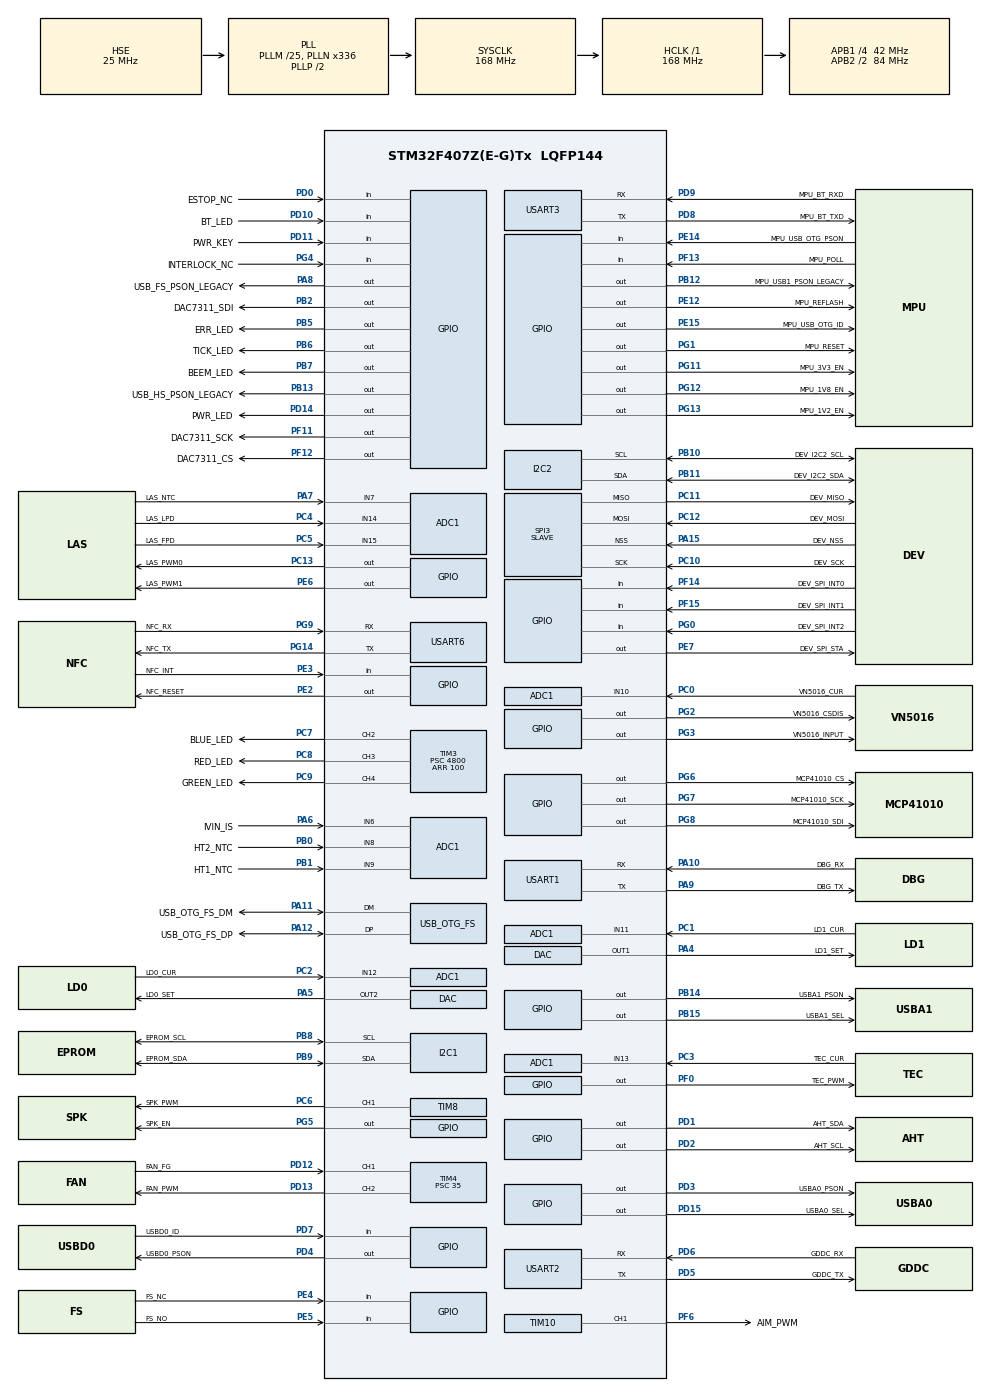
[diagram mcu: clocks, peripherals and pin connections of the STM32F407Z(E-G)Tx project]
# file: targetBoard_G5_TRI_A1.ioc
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ADC1.Channel-0\#ChannelRegularConversion=ADC_CHANNEL_6
ADC1.Channel-1\#ChannelRegularConversion=ADC_CHANNEL_7
ADC1.Channel-10\#ChannelRegularConversion=ADC_CHANNEL_TEMPSENSOR
ADC1.Channel-11\#ChannelRegularConversion=ADC_CHANNEL_VREFINT
ADC1.Channel-12\#ChannelRegularConversion=ADC_CHANNEL_VBAT
ADC1.Channel-2\#ChannelRegularConversion=ADC_CHANNEL_8
ADC1.Channel-3\#ChannelRegularConversion=ADC_CHANNEL_9
ADC1.Channel-4\#ChannelRegularConversion=ADC_CHANNEL_10
ADC1.Channel-5\#ChannelRegularConversion=ADC_CHANNEL_11
ADC1.Channel-6\#ChannelRegularConversion=ADC_CHANNEL_12
ADC1.Channel-7\#ChannelRegularConversion=ADC_CHANNEL_13
ADC1.Channel-8\#ChannelRegularConversion=ADC_CHANNEL_14
ADC1.Channel-9\#ChannelRegularConversion=ADC_CHANNEL_15
ADC1.ContinuousConvMode=ENABLE
ADC1.DMAContinuousRequests=ENABLE
ADC1.NbrOfConversion=13
ADC1.NbrOfConversionFlag=1
ADC1.Rank-0\#ChannelRegularConversion=1
ADC1.Rank-1\#ChannelRegularConversion=2
ADC1.Rank-10\#ChannelRegularConversion=11
ADC1.Rank-11\#ChannelRegularConversion=12
ADC1.Rank-12\#ChannelRegularConversion=13
ADC1.Rank-2\#ChannelRegularConversion=3
ADC1.Rank-3\#ChannelRegularConversion=4
ADC1.Rank-4\#ChannelRegularConversion=5
ADC1.Rank-5\#ChannelRegularConversion=6
ADC1.Rank-6\#ChannelRegularConversion=7
ADC1.Rank-7\#ChannelRegularConversion=8
ADC1.Rank-8\#ChannelRegularConversion=9
ADC1.Rank-9\#ChannelRegularConversion=10
ADC1.SamplingTime-0\#ChannelRegularConversion=ADC_SAMPLETIME_144CYCLES
ADC1.SamplingTime-1\#ChannelRegularConversion=ADC_SAMPLETIME_144CYCLES
ADC1.SamplingTime-10\#ChannelRegularConversion=ADC_SAMPLETIME_144CYCLES
ADC1.SamplingTime-11\#ChannelRegularConversion=ADC_SAMPLETIME_144CYCLES
ADC1.SamplingTime-12\#ChannelRegularConversion=ADC_SAMPLETIME_144CYCLES
ADC1.SamplingTime-2\#ChannelRegularConversion=ADC_SAMPLETIME_144CYCLES
ADC1.SamplingTime-3\#ChannelRegularConversion=ADC_SAMPLETIME_144CYCLES
ADC1.SamplingTime-4\#ChannelRegularConversion=ADC_SAMPLETIME_144CYCLES
ADC1.SamplingTime-5\#ChannelRegularConversion=ADC_SAMPLETIME_144CYCLES
ADC1.SamplingTime-6\#ChannelRegularConversion=ADC_SAMPLETIME_144CYCLES
ADC1.SamplingTime-7\#ChannelRegularConversion=ADC_SAMPLETIME_144CYCLES
ADC1.SamplingTime-8\#ChannelRegularConversion=ADC_SAMPLETIME_144CYCLES
ADC1.SamplingTime-9\#ChannelRegularConversion=ADC_SAMPLETIME_144CYCLES
ADC1.ScanConvMode=ENABLE
ADC1.master=1
DAC.DAC_Trigger=DAC_TRIGGER_NONE
DAC.DAC_Trigger2=DAC_TRIGGER_NONE
Dma.ADC1.0.Direction=DMA_PERIPH_TO_MEMORY
Dma.ADC1.0.FIFOMode=DMA_FIFOMODE_DISABLE
Dma.ADC1.0.Instance=DMA2_Stream0
Dma.ADC1.0.MemDataAlignment=DMA_MDATAALIGN_HALFWORD
Dma.ADC1.0.MemInc=DMA_MINC_ENABLE
Dma.ADC1.0.Mode=DMA_NORMAL
Dma.ADC1.0.PeriphDataAlignment=DMA_PDATAALIGN_HALFWORD
Dma.ADC1.0.PeriphInc=DMA_PINC_DISABLE
Dma.ADC1.0.Priority=DMA_PRIORITY_LOW
Dma.Request0=ADC1
Dma.Request1=USART1_RX
Dma.USART1_RX.1.Direction=DMA_PERIPH_TO_MEMORY
Dma.USART1_RX.1.FIFOMode=DMA_FIFOMODE_DISABLE
Dma.USART1_RX.1.Instance=DMA2_Stream2
Dma.USART1_RX.1.MemDataAlignment=DMA_MDATAALIGN_BYTE
Dma.USART1_RX.1.MemInc=DMA_MINC_ENABLE
Dma.USART1_RX.1.Mode=DMA_NORMAL
Dma.USART1_RX.1.PeriphDataAlignment=DMA_PDATAALIGN_BYTE
Dma.USART1_RX.1.PeriphInc=DMA_PINC_DISABLE
Dma.USART1_RX.1.Priority=DMA_PRIORITY_MEDIUM
FATFS._CODE_PAGE=437
FATFS._FS_EXFAT=1
FATFS._FS_LOCK=255
FATFS._LFN_UNICODE=0
FATFS._MAX_SS=512
FATFS._STRF_ENCODE=0
FATFS._USE_CHMOD=1
FATFS._USE_EXPAND=1
FATFS._USE_FIND=1
FATFS._USE_FORWARD=1
FATFS._USE_LABEL=1
FATFS._USE_LFN=3
FATFS._USE_MUTEX=1
FREERTOS.HEAP_NUMBER=4
FREERTOS.Tasks01=defaultTask,24,512,StartDefaultTask,Default,NULL,Dynamic,NULL,NULL;mainAppTask,24,10240,StartMainAppTask,As external,NULL,Dynamic,NULL,NULL
FREERTOS.configENABLE_FPU=1
FREERTOS.configMINIMAL_STACK_SIZE=512
FREERTOS.configTOTAL_HEAP_SIZE=49152
FREERTOS.configUSE_APPLICATION_TASK_TAG=1
I2C1.I2C_Mode=I2C_Fast
Mcu.Family=STM32F4
Mcu.Name=STM32F407Z(E-G)Tx
Mcu.Package=LQFP144
NVIC.DMA2_Stream0_IRQn=true\:8\:0\:true\:false\:true\:true\:false\:true\:true
NVIC.DMA2_Stream2_IRQn=true\:8\:0\:true\:false\:true\:true\:false\:true\:true
NVIC.OTG_FS_IRQn=true\:9\:0\:true\:false\:true\:true\:false\:true\:true
NVIC.PriorityGroup=NVIC_PRIORITYGROUP_4
NVIC.TIM7_IRQn=true\:6\:0\:true\:false\:true\:true\:true\:true\:true
NVIC.TIM8_TRG_COM_TIM14_IRQn=true\:7\:0\:true\:false\:true\:true\:true\:true\:true
NVIC.TIM8_UP_TIM13_IRQn=true\:5\:0\:true\:false\:true\:false\:false\:true\:true
NVIC.TimeBase=TIM8_UP_TIM13_IRQn
NVIC.TimeBaseIP=TIM13
NVIC.USART2_IRQn=true\:5\:0\:false\:false\:true\:true\:true\:true\:true
PA10.GPIO_Label=DBG_RX
PA10.GPIO_PuPd=GPIO_PULLDOWN
PA10.GPIO_Speed=GPIO_SPEED_FREQ_LOW
PA10.Mode=Asynchronous
PA10.Signal=USART1_RX
PA11.GPIO_Label=USB_OTG_FS_DM
PA11.Mode=Host_Only
PA11.Signal=USB_OTG_FS_DM
PA12.GPIO_Label=USB_OTG_FS_DP
PA12.Mode=Host_Only
PA12.Signal=USB_OTG_FS_DP
PA13.Mode=Trace_Asynchronous_SW
PA13.Signal=SYS_JTMS-SWDIO
PA14.Mode=Trace_Asynchronous_SW
PA14.Signal=SYS_JTCK-SWCLK
PA15.GPIO_Label=DEV_NSS
PA15.GPIO_PuPd=GPIO_PULLUP
PA15.Mode=NSS_Signal_Hard_Input
PA15.Signal=SPI3_NSS
PA4.GPIO_Label=LD1_SET
PA4.Signal=COMP_DAC1_group
PA5.GPIO_Label=LD0_SET
PA5.Signal=COMP_DAC2_group
PA6.GPIO_Label=IVIN_IS
PA6.Signal=ADCx_IN6
PA7.GPIO_Label=LAS_NTC
PA7.Signal=ADCx_IN7
PA8.GPIO_Label=USB_FS_PSON_LEGACY
PA8.GPIO_PuPd=GPIO_PULLDOWN
PA8.Signal=GPIO_Output
PA9.GPIO_Label=DBG_TX
PA9.GPIO_PuPd=GPIO_PULLDOWN
PA9.GPIO_Speed=GPIO_SPEED_FREQ_LOW
PA9.Mode=Asynchronous
PA9.Signal=USART1_TX
PB0.GPIO_Label=HT2_NTC
PB0.Signal=ADCx_IN8
PB1.GPIO_Label=HT1_NTC
PB1.Signal=ADCx_IN9
PB10.GPIO_Label=DEV_I2C2_SCL
PB10.Mode=I2C
PB10.Signal=I2C2_SCL
PB11.GPIO_Label=DEV_I2C2_SDA
PB11.Mode=I2C
PB11.Signal=I2C2_SDA
PB12.GPIO_Label=MPU_USB1_PSON_LEGACY
PB12.GPIO_PuPd=GPIO_PULLDOWN
PB12.Signal=GPIO_Output
PB13.GPIO_Label=USB_HS_PSON_LEGACY
PB13.Signal=GPIO_Output
PB14.GPIO_Label=USBA1_PSON
PB14.Signal=GPIO_Output
PB15.GPIO_Label=USBA1_SEL
PB15.Signal=GPIO_Output
PB2.GPIO_Label=DAC7311_SDI
PB2.GPIO_PuPd=GPIO_PULLDOWN
PB2.GPIO_Speed=GPIO_SPEED_FREQ_HIGH
PB2.Signal=GPIO_Output
PB3.Mode=Trace_Asynchronous_SW
PB3.Signal=SYS_JTDO-SWO
PB5.GPIO_Label=ERR_LED
PB5.GPIO_PuPd=GPIO_NOPULL
PB5.Signal=GPIO_Output
PB6.GPIO_Label=TICK_LED
PB6.GPIO_PuPd=GPIO_NOPULL
PB6.Signal=GPIO_Output
PB7.GPIO_Label=BEEM_LED
PB7.GPIO_PuPd=GPIO_NOPULL
PB7.Signal=GPIO_Output
PB8.GPIO_Label=EPROM_SCL
PB8.Mode=I2C
PB8.Signal=I2C1_SCL
PB9.GPIO_Label=EPROM_SDA
PB9.Mode=I2C
PB9.Signal=I2C1_SDA
PC0.GPIO_Label=VN5016_CUR
PC0.Signal=ADCx_IN10
PC1.GPIO_Label=LD1_CUR
PC1.Signal=ADCx_IN11
PC10.GPIO_Label=DEV_SCK
PC10.GPIO_PuPd=GPIO_PULLDOWN
PC10.Mode=Full_Duplex_Slave
PC10.Signal=SPI3_SCK
PC11.GPIO_Label=DEV_MISO
PC11.GPIO_PuPd=GPIO_PULLDOWN
PC11.Mode=Full_Duplex_Slave
PC11.Signal=SPI3_MISO
PC12.GPIO_Label=DEV_MOSI
PC12.GPIO_PuPd=GPIO_PULLDOWN
PC12.Mode=Full_Duplex_Slave
PC12.Signal=SPI3_MOSI
PC13-ANTI_TAMP.GPIO_Label=LAS_PWM0
PC13-ANTI_TAMP.GPIO_PuPd=GPIO_NOPULL
PC13-ANTI_TAMP.Signal=GPIO_Output
PC2.GPIO_Label=LD0_CUR
PC2.Signal=ADCx_IN12
PC3.GPIO_Label=TEC_CUR
PC3.Signal=ADCx_IN13
PC4.GPIO_Label=LAS_LPD
PC4.Signal=ADCx_IN14
PC5.GPIO_Label=LAS_FPD
PC5.Signal=ADCx_IN15
PC6.GPIO_Label=SPK_PWM
PC6.GPIO_PuPd=GPIO_PULLDOWN
PC6.Signal=S_TIM8_CH1
PC7.GPIO_Label=BLUE_LED
PC7.GPIO_PuPd=GPIO_NOPULL
PC7.Signal=S_TIM3_CH2
PC8.GPIO_Label=RED_LED
PC8.Signal=S_TIM3_CH3
PC9.GPIO_Label=GREEN_LED
PC9.Signal=S_TIM3_CH4
PD0.GPIO_Label=ESTOP_NC
PD0.GPIO_PuPd=GPIO_NOPULL
PD0.Signal=GPIO_Input
PD1.GPIO_Label=AHT_SDA
PD1.GPIO_Speed=GPIO_SPEED_FREQ_HIGH
PD1.Signal=GPIO_Output
PD10.GPIO_Label=BT_LED
PD10.Signal=GPIO_Input
PD11.GPIO_Label=PWR_KEY
PD11.GPIO_PuPd=GPIO_NOPULL
PD11.Signal=GPIO_Input
PD12.GPIO_Label=FAN_FG
PD12.GPIO_ModeDefaultPP=GPIO_MODE_AF_OD
PD12.Signal=S_TIM4_CH1
PD13.GPIO_Label=FAN_PWM
PD13.GPIO_ModeDefaultPP=GPIO_MODE_AF_OD
PD13.Signal=S_TIM4_CH2
PD14.GPIO_Label=PWR_LED
PD14.GPIO_PuPd=GPIO_NOPULL
PD14.Signal=GPIO_Output
PD15.GPIO_Label=USBA0_SEL
PD15.GPIO_PuPd=GPIO_NOPULL
PD15.Signal=GPIO_Output
PD2.GPIO_Label=AHT_SCL
PD2.GPIO_Speed=GPIO_SPEED_FREQ_HIGH
PD2.Signal=GPIO_Output
PD3.GPIO_Label=USBA0_PSON
PD3.Signal=GPIO_Output
PD4.GPIO_Label=USBD0_PSON
PD4.Signal=GPIO_Output
PD5.GPIO_Label=GDDC_TX
PD5.GPIO_PuPd=GPIO_PULLDOWN
PD5.GPIO_Speed=GPIO_SPEED_FREQ_LOW
PD5.Mode=Asynchronous
PD5.Signal=USART2_TX
PD6.GPIO_Label=GDDC_RX
PD6.GPIO_PuPd=GPIO_PULLDOWN
PD6.GPIO_Speed=GPIO_SPEED_FREQ_LOW
PD6.Mode=Asynchronous
PD6.Signal=USART2_RX
PD7.GPIO_Label=USBD0_ID
PD7.Signal=GPIO_Input
PD8.GPIO_Label=MPU_BT_TXD
PD8.GPIO_PuPd=GPIO_PULLDOWN
PD8.GPIO_Speed=GPIO_SPEED_FREQ_LOW
PD8.Mode=Asynchronous
PD8.Signal=USART3_TX
PD9.GPIO_Label=MPU_BT_RXD
PD9.GPIO_PuPd=GPIO_PULLDOWN
PD9.GPIO_Speed=GPIO_SPEED_FREQ_LOW
PD9.Mode=Asynchronous
PD9.Signal=USART3_RX
PE12.GPIO_Label=MPU_REFLASH
PE12.GPIO_PuPd=GPIO_PULLDOWN
PE12.Signal=GPIO_Output
PE14.GPIO_Label=MPU_USB_OTG_PSON
PE14.Signal=GPIO_Input
PE15.GPIO_Label=MPU_USB_OTG_ID
PE15.GPIO_PuPd=GPIO_PULLDOWN
PE15.Signal=GPIO_Output
PE2.GPIO_Label=NFC_RESET
PE2.GPIO_PuPd=GPIO_PULLUP
PE2.Signal=GPIO_Output
PE3.GPIO_Label=NFC_INT
PE3.GPIO_PuPd=GPIO_PULLUP
PE3.Signal=GPIO_Input
PE4.GPIO_Label=FS_NC
PE4.Signal=GPIO_Input
PE5.GPIO_Label=FS_NO
PE5.Signal=GPIO_Input
PE6.GPIO_Label=LAS_PWM1
PE6.GPIO_PuPd=GPIO_NOPULL
PE6.Signal=GPIO_Output
PE7.GPIO_Label=DEV_SPI_STA
PE7.GPIO_PuPd=GPIO_PULLDOWN
PE7.Signal=GPIO_Output
PF0.GPIO_Label=TEC_PWM
PF0.GPIO_PuPd=GPIO_NOPULL
PF0.Signal=GPIO_Output
PF11.GPIO_Label=DAC7311_SCK
PF11.GPIO_PuPd=GPIO_PULLDOWN
PF11.GPIO_Speed=GPIO_SPEED_FREQ_HIGH
PF11.Signal=GPIO_Output
PF12.GPIO_Label=DAC7311_CS
PF12.GPIO_PuPd=GPIO_PULLUP
PF12.GPIO_Speed=GPIO_SPEED_FREQ_HIGH
PF12.Signal=GPIO_Output
PF13.GPIO_Label=MPU_POLL
PF13.Signal=GPIO_Input
PF14.GPIO_Label=DEV_SPI_INT0
PF14.Signal=GPIO_Input
PF15.GPIO_Label=DEV_SPI_INT1
PF15.Signal=GPIO_Input
PF6.GPIO_Label=AIM_PWM
PF6.Signal=S_TIM10_CH1
PG0.GPIO_Label=DEV_SPI_INT2
PG0.Signal=GPIO_Input
PG1.GPIO_Label=MPU_RESET
PG1.GPIO_PuPd=GPIO_PULLDOWN
PG1.Signal=GPIO_Output
PG11.GPIO_Label=MPU_3V3_EN
PG11.Signal=GPIO_Output
PG12.GPIO_Label=MPU_1V8_EN
PG12.Signal=GPIO_Output
PG13.GPIO_Label=MPU_1V2_EN
PG13.Signal=GPIO_Output
PG14.GPIO_Label=NFC_TX
PG14.GPIO_PuPd=GPIO_PULLDOWN
PG14.GPIO_Speed=GPIO_SPEED_FREQ_LOW
PG14.Mode=Asynchronous
PG14.Signal=USART6_TX
PG2.GPIO_Label=VN5016_CSDIS
PG2.GPIO_PuPd=GPIO_PULLDOWN
PG2.Signal=GPIO_Output
PG3.GPIO_Label=VN5016_INPUT
PG3.GPIO_PuPd=GPIO_PULLUP
PG3.Signal=GPIO_Output
PG4.GPIO_Label=INTERLOCK_NC
PG4.Signal=GPIO_Input
PG5.GPIO_Label=SPK_EN
PG5.Signal=GPIO_Output
PG6.GPIO_Label=MCP41010_CS
PG6.GPIO_PuPd=GPIO_PULLUP
PG6.GPIO_Speed=GPIO_SPEED_FREQ_HIGH
PG6.Signal=GPIO_Output
PG7.GPIO_Label=MCP41010_SCK
PG7.GPIO_PuPd=GPIO_PULLDOWN
PG7.GPIO_Speed=GPIO_SPEED_FREQ_HIGH
PG7.Signal=GPIO_Output
PG8.GPIO_Label=MCP41010_SDI
PG8.GPIO_PuPd=GPIO_PULLDOWN
PG8.GPIO_Speed=GPIO_SPEED_FREQ_HIGH
PG8.Signal=GPIO_Output
PG9.GPIO_Label=NFC_RX
PG9.GPIO_PuPd=GPIO_PULLDOWN
PG9.GPIO_Speed=GPIO_SPEED_FREQ_LOW
PG9.Mode=Asynchronous
PG9.Signal=USART6_RX
PH0-OSC_IN.Mode=HSE-External-Oscillator
PH0-OSC_IN.Signal=RCC_OSC_IN
PH1-OSC_OUT.Mode=HSE-External-Oscillator
PH1-OSC_OUT.Signal=RCC_OSC_OUT
ProjectManager.HeapSize=0x2000
ProjectManager.StackSize=0x1000
ProjectManager.TargetToolchain=MDK-ARM V5.32
RCC.48MHZClocksFreq_Value=48000000
RCC.AHBFreq_Value=168000000
RCC.APB1CLKDivider=RCC_HCLK_DIV4
RCC.APB1Freq_Value=42000000
RCC.APB1TimFreq_Value=84000000
RCC.APB2CLKDivider=RCC_HCLK_DIV2
RCC.APB2Freq_Value=84000000
RCC.APB2TimFreq_Value=168000000
RCC.CortexFreq_Value=168000000
RCC.HCLKFreq_Value=168000000
RCC.HSE_VALUE=25000000
RCC.HSI_VALUE=16000000
RCC.LSE_VALUE=32768
RCC.PLLM=25
RCC.PLLN=336
RCC.PLLQ=7
RCC.SYSCLKFreq_VALUE=168000000
RCC.SYSCLKSource=RCC_SYSCLKSOURCE_PLLCLK
RCC.VCOOutputFreq_Value=336000000
RTC.Format=RTC_FORMAT_BIN
SH.ADCx_IN10.0=ADC1_IN10,IN10
SH.ADCx_IN11.0=ADC1_IN11,IN11
SH.ADCx_IN12.0=ADC1_IN12,IN12
SH.ADCx_IN13.0=ADC1_IN13,IN13
SH.ADCx_IN14.0=ADC1_IN14,IN14
SH.ADCx_IN15.0=ADC1_IN15,IN15
SH.ADCx_IN6.0=ADC1_IN6,IN6
SH.ADCx_IN7.0=ADC1_IN7,IN7
SH.ADCx_IN8.0=ADC1_IN8,IN8
SH.ADCx_IN9.0=ADC1_IN9,IN9
SH.COMP_DAC1_group.0=DAC_OUT1,DAC_OUT1
SH.COMP_DAC2_group.0=DAC_OUT2,DAC_OUT2
SH.S_TIM10_CH1.0=TIM10_CH1,PWM Generation1 CH1
SH.S_TIM3_CH2.0=TIM3_CH2,PWM Generation2 CH2
SH.S_TIM3_CH3.0=TIM3_CH3,PWM Generation3 CH3
SH.S_TIM3_CH4.0=TIM3_CH4,PWM Generation4 CH4
SH.S_TIM4_CH1.0=TIM4_CH1,Input_Capture1_from_TI1
SH.S_TIM4_CH2.0=TIM4_CH2,PWM Generation2 CH2
SH.S_TIM8_CH1.0=TIM8_CH1,Output Compare1 CH1
SPI3.CRCCalculation=SPI_CRCCALCULATION_ENABLE
SPI3.Direction=SPI_DIRECTION_2LINES
SPI3.Mode=SPI_MODE_SLAVE
SPI3.VirtualNSS=VM_NSSHARD
SPI3.VirtualType=VM_SLAVE
TIM10.AutoReloadPreload=TIM_AUTORELOAD_PRELOAD_ENABLE
TIM10.Channel=TIM_CHANNEL_1
TIM10.Period=5000
TIM10.Prescaler=96
TIM14.Period=1000
TIM14.Prescaler=84
TIM3.AutoReloadPreload=TIM_AUTORELOAD_PRELOAD_ENABLE
TIM3.Channel-PWM\ Generation2\ CH2=TIM_CHANNEL_2
TIM3.Channel-PWM\ Generation3\ CH3=TIM_CHANNEL_3
TIM3.Channel-PWM\ Generation4\ CH4=TIM_CHANNEL_4
TIM3.Period=100
TIM3.Prescaler=4800
TIM4.AutoReloadPreload=TIM_AUTORELOAD_PRELOAD_ENABLE
TIM4.Channel-Input_Capture1_from_TI1=TIM_CHANNEL_1
TIM4.Channel-PWM\ Generation2\ CH2=TIM_CHANNEL_2
TIM4.Period=100
TIM4.Prescaler=35
TIM7.AutoReloadPreload=TIM_AUTORELOAD_PRELOAD_ENABLE
TIM7.Period=1000
TIM7.Prescaler=84
TIM8.AutoReloadPreload=TIM_AUTORELOAD_PRELOAD_ENABLE
TIM8.Channel-Output\ Compare1\ CH1=TIM_CHANNEL_1
TIM8.ClockDivision=TIM_CLOCKDIVISION_DIV1
TIM8.OC1Preload=ENABLE
TIM8.OCMode_1=TIM_OCMODE_TOGGLE
TIM8.Period=1000
TIM8.Prescaler=2000
TIM8.Pulse-Output\ Compare1\ CH1=1
USART1.VirtualMode=VM_ASYNC
USART2.VirtualMode=VM_ASYNC
USART3.VirtualMode=VM_ASYNC
USART6.VirtualMode=VM_ASYNC
USB_HOST.USBH_DEBUG_LEVEL-ALL_Classes_FS=3
USB_HOST.USBH_HandleTypeDef-ALL_Classes_FS=hUsbHostFS
USB_HOST.VirtualModeFS=All_Classes
USB_OTG_FS.VirtualMode=Host_Only
USB_OTG_FS.phy_itface=HCD_PHY_EMBEDDED
VP_ADC1_TempSens_Input.Mode=IN-TempSens
VP_ADC1_Vbat_Input.Mode=IN-Vbat
VP_ADC1_Vref_Input.Mode=IN-Vrefint
VP_CRC_VS_CRC.Mode=CRC_Activate
VP_FATFS_VS_USB.Mode=USB
VP_FREERTOS_VS_CMSIS_V2.Mode=CMSIS_V2
VP_RNG_VS_RNG.Mode=RNG_Activate
VP_RTC_VS_RTC_Activate.Mode=RTC_Enabled
VP_RTC_VS_RTC_Calendar.Mode=RTC_Calendar
VP_SYS_VS_tim13.Mode=TIM13
VP_TIM10_VS_ClockSourceINT.Mode=Enable_Timer
VP_TIM14_VS_ClockSourceINT.Mode=Enable_Timer
VP_TIM3_VS_ClockSourceINT.Mode=Internal
VP_TIM4_VS_ClockSourceINT.Mode=Internal
VP_TIM7_VS_ClockSourceINT.Mode=Enable_Timer
VP_TIM8_VS_ClockSourceINT.Mode=Internal
VP_USB_HOST_VS_USB_HOST_ALL_CLASS_FS.Mode=ALL_Classes_FS
board=custom

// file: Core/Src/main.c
/* USER CODE BEGIN Header */
/**
  ******************************************************************************
  * @file           : main.c
  * @brief          : Main program body
  ******************************************************************************
  * @attention
  *
  * Copyright (c) 2025 STMicroelectronics.
  * All rights reserved.
  *
  * This software is licensed under terms that can be found in the LICENSE file
  * in the root directory of this software component.
  * If no LICENSE file comes with this software, it is provided AS-IS.
  *
  ******************************************************************************
  */
/* USER CODE END Header */
#include "main.h"
#include "cmsis_os.h"
#include "adc.h"
#include "crc.h"
#include "dac.h"
#include "dma.h"
#include "fatfs.h"
#include "i2c.h"
#include "rng.h"
#include "rtc.h"
#include "spi.h"
#include "tim.h"
#include "usart.h"
#include "usb_host.h"
#include "gpio.h"

/* USER CODE BEGIN Includes */
#include "sPlc.h"
/* USER CODE END Includes */

void SystemClock_Config(void);
void MX_FREERTOS_Init(void);

int main(void)
{

  /* USER CODE BEGIN 1 */
	resetInit();
  /* USER CODE END 1 */

  /* MCU Configuration--------------------------------------------------------*/

  /* Reset of all peripherals, Initializes the Flash interface and the Systick. */
  HAL_Init();

  /* Configure the system clock */
  SystemClock_Config();

  /* Initialize all configured peripherals */
  MX_GPIO_Init();
  MX_DMA_Init();
  MX_DAC_Init();
  MX_SPI3_Init();
  MX_ADC1_Init();
  MX_CRC_Init();
  MX_I2C2_Init();
  MX_RNG_Init();
  MX_TIM3_Init();
  MX_TIM4_Init();
  MX_TIM8_Init();
  MX_USART1_UART_Init();
  MX_USART2_UART_Init();
  MX_USART3_UART_Init();
  MX_I2C1_Init();
  MX_TIM10_Init();
  MX_USART6_UART_Init();
  MX_TIM14_Init();
  MX_TIM7_Init();
  MX_FATFS_Init();
  MX_RTC_Init();

  /* Init scheduler */
  osKernelInitialize();  /* Call init function for freertos objects (in cmsis_os2.c) */
  MX_FREERTOS_Init();

  /* Start scheduler */
  osKernelStart();

  /* We should never get here as control is now taken by the scheduler */

  /* Infinite loop */
  while (1)
  {

  }
}

void SystemClock_Config(void)
{
  RCC_OscInitTypeDef RCC_OscInitStruct = {0};
  RCC_ClkInitTypeDef RCC_ClkInitStruct = {0};

  /** Configure the main internal regulator output voltage
  */
  __HAL_RCC_PWR_CLK_ENABLE();
  __HAL_PWR_VOLTAGESCALING_CONFIG(PWR_REGULATOR_VOLTAGE_SCALE1);

  /** Initializes the RCC Oscillators according to the specified parameters
  * in the RCC_OscInitTypeDef structure.
  */
  RCC_OscInitStruct.OscillatorType = RCC_OSCILLATORTYPE_LSI|RCC_OSCILLATORTYPE_HSE;
  RCC_OscInitStruct.HSEState = RCC_HSE_ON;
  RCC_OscInitStruct.LSIState = RCC_LSI_ON;
  RCC_OscInitStruct.PLL.PLLState = RCC_PLL_ON;
  RCC_OscInitStruct.PLL.PLLSource = RCC_PLLSOURCE_HSE;
  RCC_OscInitStruct.PLL.PLLM = 25;
  RCC_OscInitStruct.PLL.PLLN = 336;
  RCC_OscInitStruct.PLL.PLLP = RCC_PLLP_DIV2;
  RCC_OscInitStruct.PLL.PLLQ = 7;
  if (HAL_RCC_OscConfig(&RCC_OscInitStruct) != HAL_OK)
  {
    Error_Handler();
  }

  /** Initializes the CPU, AHB and APB buses clocks
  */
  RCC_ClkInitStruct.ClockType = RCC_CLOCKTYPE_HCLK|RCC_CLOCKTYPE_SYSCLK
                              |RCC_CLOCKTYPE_PCLK1|RCC_CLOCKTYPE_PCLK2;
  RCC_ClkInitStruct.SYSCLKSource = RCC_SYSCLKSOURCE_PLLCLK;
  RCC_ClkInitStruct.AHBCLKDivider = RCC_SYSCLK_DIV1;
  RCC_ClkInitStruct.APB1CLKDivider = RCC_HCLK_DIV4;
  RCC_ClkInitStruct.APB2CLKDivider = RCC_HCLK_DIV2;

  if (HAL_RCC_ClockConfig(&RCC_ClkInitStruct, FLASH_LATENCY_5) != HAL_OK)
  {
    Error_Handler();
  }
}

void HAL_TIM_PeriodElapsedCallback(TIM_HandleTypeDef *htim)
{
  if (htim->Instance == TIM13)
  {
    HAL_IncTick();
  }
  /* USER CODE BEGIN Callback 1 */
	if(htim->Instance == CONFIG_SPLC_TIM) {
		sPlcTimerIsr();
	}
	if(htim->Instance == CONFIG_LASER_TIM){
		sPlcLaserTimerIsr();
	}
  /* USER CODE END Callback 1 */
}

void Error_Handler(void)
{
  __disable_irq();
  while (1)
  {
  }
}

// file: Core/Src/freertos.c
/* USER CODE BEGIN Header */
/**
  ******************************************************************************
  * File Name          : freertos.c
  * Description        : Code for freertos applications
  ******************************************************************************
  * @attention
  *
  * Copyright (c) 2025 STMicroelectronics.
  * All rights reserved.
  *
  * This software is licensed under terms that can be found in the LICENSE file
  * in the root directory of this software component.
  * If no LICENSE file comes with this software, it is provided AS-IS.
  *
  ******************************************************************************
  */
/* USER CODE END Header */

#include "FreeRTOS.h"
#include "task.h"
#include "main.h"
#include "cmsis_os.h"

/* USER CODE BEGIN Includes */
#include "mainApp.h"
/* USER CODE END Includes */

/* Definitions for defaultTask */
osThreadId_t defaultTaskHandle;
const osThreadAttr_t defaultTask_attributes = {
  .name = "defaultTask",
  .stack_size = 512 * 4,
  .priority = (osPriority_t) osPriorityNormal,
};
/* Definitions for mainAppTask */
osThreadId_t mainAppTaskHandle;
const osThreadAttr_t mainAppTask_attributes = {
  .name = "mainAppTask",
  .stack_size = 10240 * 4,
  .priority = (osPriority_t) osPriorityNormal,
};

void StartDefaultTask(void *argument);
extern void StartMainAppTask(void *argument);

extern void MX_USB_HOST_Init(void);
void MX_FREERTOS_Init(void); /* (MISRA C 2004 rule 8.1) */

void MX_FREERTOS_Init(void) {

  /* Create the thread(s) */
  /* creation of defaultTask */
  defaultTaskHandle = osThreadNew(StartDefaultTask, NULL, &defaultTask_attributes);

  /* creation of mainAppTask */
  mainAppTaskHandle = osThreadNew(StartMainAppTask, NULL, &mainAppTask_attributes);

  /* USER CODE BEGIN RTOS_THREADS */
  /* add threads, ... */

	//testTaskHandle = osThreadNew(testTask, NULL, &testTask_attributes);
  /* USER CODE END RTOS_THREADS */

}

void StartDefaultTask(void *argument)
{
  /* init code for USB_HOST */
  MX_USB_HOST_Init();
  for(;;)
  {
    osDelay(1);
  }
}

/* USER CODE BEGIN Application */
void testTask(void *argument){
	while(1){
		vTaskDelay(100);
	}
}
/* USER CODE END Application */
